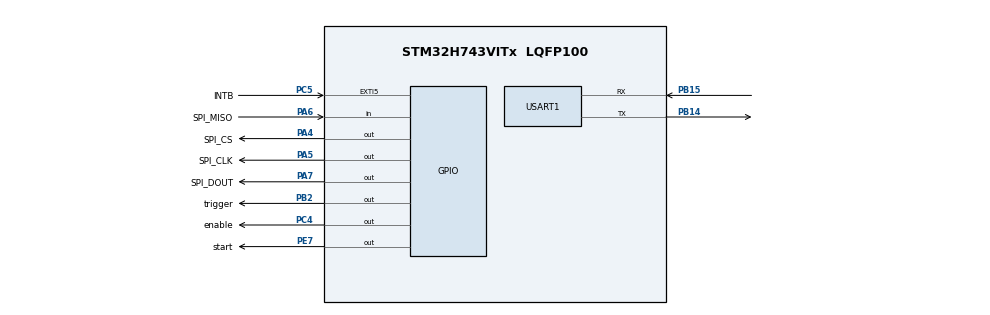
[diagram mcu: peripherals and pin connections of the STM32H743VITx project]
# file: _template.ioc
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CORTEX_M7.AccessPermission-Cortex_Memory_Protection_Unit_Region0_Settings=MPU_REGION_FULL_ACCESS
CORTEX_M7.AccessPermission-Cortex_Memory_Protection_Unit_Region1_Settings=MPU_REGION_FULL_ACCESS
CORTEX_M7.AccessPermission-Cortex_Memory_Protection_Unit_Region2_Settings=MPU_REGION_FULL_ACCESS
CORTEX_M7.AccessPermission-Cortex_Memory_Protection_Unit_Region3_Settings=MPU_REGION_FULL_ACCESS
CORTEX_M7.AccessPermission-Cortex_Memory_Protection_Unit_Region4_Settings=MPU_REGION_FULL_ACCESS
CORTEX_M7.BaseAddress-Cortex_Memory_Protection_Unit_Region0_Settings=0x24000000
CORTEX_M7.BaseAddress-Cortex_Memory_Protection_Unit_Region1_Settings=0x30000000
CORTEX_M7.BaseAddress-Cortex_Memory_Protection_Unit_Region2_Settings=0x30020000
CORTEX_M7.BaseAddress-Cortex_Memory_Protection_Unit_Region3_Settings=0x30040000
CORTEX_M7.BaseAddress-Cortex_Memory_Protection_Unit_Region4_Settings=0x38000000
CORTEX_M7.CPU_DCache=Enabled
CORTEX_M7.CPU_ICache=Enabled
CORTEX_M7.Enable-Cortex_Memory_Protection_Unit_Region0_Settings=MPU_REGION_ENABLE
CORTEX_M7.Enable-Cortex_Memory_Protection_Unit_Region1_Settings=MPU_REGION_ENABLE
CORTEX_M7.Enable-Cortex_Memory_Protection_Unit_Region2_Settings=MPU_REGION_ENABLE
CORTEX_M7.Enable-Cortex_Memory_Protection_Unit_Region3_Settings=MPU_REGION_ENABLE
CORTEX_M7.Enable-Cortex_Memory_Protection_Unit_Region4_Settings=MPU_REGION_ENABLE
CORTEX_M7.IsBufferable-Cortex_Memory_Protection_Unit_Region0_Settings=MPU_ACCESS_BUFFERABLE
CORTEX_M7.IsCacheable-Cortex_Memory_Protection_Unit_Region0_Settings=MPU_ACCESS_CACHEABLE
CORTEX_M7.MPU_Control=MPU_PRIVILEGED_DEFAULT
CORTEX_M7.Size-Cortex_Memory_Protection_Unit_Region0_Settings=MPU_REGION_SIZE_512KB
CORTEX_M7.Size-Cortex_Memory_Protection_Unit_Region1_Settings=MPU_REGION_SIZE_128KB
CORTEX_M7.Size-Cortex_Memory_Protection_Unit_Region2_Settings=MPU_REGION_SIZE_128KB
CORTEX_M7.Size-Cortex_Memory_Protection_Unit_Region3_Settings=MPU_REGION_SIZE_32KB
CORTEX_M7.Size-Cortex_Memory_Protection_Unit_Region4_Settings=MPU_REGION_SIZE_64KB
CORTEX_M7.TypeExtField-Cortex_Memory_Protection_Unit_Region0_Settings=MPU_TEX_LEVEL1
CORTEX_M7.TypeExtField-Cortex_Memory_Protection_Unit_Region1_Settings=MPU_TEX_LEVEL1
CORTEX_M7.TypeExtField-Cortex_Memory_Protection_Unit_Region2_Settings=MPU_TEX_LEVEL1
CORTEX_M7.TypeExtField-Cortex_Memory_Protection_Unit_Region3_Settings=MPU_TEX_LEVEL1
CORTEX_M7.TypeExtField-Cortex_Memory_Protection_Unit_Region4_Settings=MPU_TEX_LEVEL1
Dma.Request0=USART1_RX
Dma.Request1=USART1_TX
Dma.USART1_RX.0.Direction=DMA_PERIPH_TO_MEMORY
Dma.USART1_RX.0.EventEnable=DISABLE
Dma.USART1_RX.0.FIFOMode=DMA_FIFOMODE_DISABLE
Dma.USART1_RX.0.Instance=DMA1_Stream0
Dma.USART1_RX.0.MemDataAlignment=DMA_MDATAALIGN_BYTE
Dma.USART1_RX.0.MemInc=DMA_MINC_ENABLE
Dma.USART1_RX.0.Mode=DMA_NORMAL
Dma.USART1_RX.0.PeriphDataAlignment=DMA_PDATAALIGN_BYTE
Dma.USART1_RX.0.PeriphInc=DMA_PINC_DISABLE
Dma.USART1_RX.0.Polarity=HAL_DMAMUX_REQ_GEN_RISING
Dma.USART1_RX.0.Priority=DMA_PRIORITY_LOW
Dma.USART1_RX.0.RequestNumber=1
Dma.USART1_RX.0.SignalID=NONE
Dma.USART1_RX.0.SyncEnable=DISABLE
Dma.USART1_RX.0.SyncPolarity=HAL_DMAMUX_SYNC_NO_EVENT
Dma.USART1_RX.0.SyncRequestNumber=1
Dma.USART1_RX.0.SyncSignalID=NONE
Dma.USART1_TX.1.Direction=DMA_MEMORY_TO_PERIPH
Dma.USART1_TX.1.EventEnable=DISABLE
Dma.USART1_TX.1.FIFOMode=DMA_FIFOMODE_DISABLE
Dma.USART1_TX.1.Instance=DMA1_Stream1
Dma.USART1_TX.1.MemDataAlignment=DMA_MDATAALIGN_BYTE
Dma.USART1_TX.1.MemInc=DMA_MINC_ENABLE
Dma.USART1_TX.1.Mode=DMA_NORMAL
Dma.USART1_TX.1.PeriphDataAlignment=DMA_PDATAALIGN_BYTE
Dma.USART1_TX.1.PeriphInc=DMA_PINC_DISABLE
Dma.USART1_TX.1.Polarity=HAL_DMAMUX_REQ_GEN_RISING
Dma.USART1_TX.1.Priority=DMA_PRIORITY_LOW
Dma.USART1_TX.1.RequestNumber=1
Dma.USART1_TX.1.SignalID=NONE
Dma.USART1_TX.1.SyncEnable=DISABLE
Dma.USART1_TX.1.SyncPolarity=HAL_DMAMUX_SYNC_NO_EVENT
Dma.USART1_TX.1.SyncRequestNumber=1
Dma.USART1_TX.1.SyncSignalID=NONE
Mcu.Family=STM32H7
Mcu.Name=STM32H743VITx
Mcu.Package=LQFP100
NVIC.DMA1_Stream0_IRQn=true\:0\:0\:false\:false\:true\:false\:true\:true
NVIC.DMA1_Stream1_IRQn=true\:0\:0\:false\:false\:true\:false\:true\:true
NVIC.EXTI9_5_IRQn=true\:0\:0\:false\:false\:true\:true\:true\:true
NVIC.PriorityGroup=NVIC_PRIORITYGROUP_4
NVIC.USART1_IRQn=true\:0\:0\:false\:false\:true\:true\:true\:true
PA13\ (JTMS/SWDIO).Mode=Serial_Wire
PA13\ (JTMS/SWDIO).Signal=DEBUG_JTMS-SWDIO
PA14\ (JTCK/SWCLK).Mode=Serial_Wire
PA14\ (JTCK/SWCLK).Signal=DEBUG_JTCK-SWCLK
PA4.GPIO_Label=SPI_CS
PA4.GPIO_Speed=GPIO_SPEED_FREQ_VERY_HIGH
PA4.PinState=GPIO_PIN_SET
PA4.Signal=GPIO_Output
PA5.GPIO_Label=SPI_CLK
PA5.GPIO_Speed=GPIO_SPEED_FREQ_VERY_HIGH
PA5.PinState=GPIO_PIN_RESET
PA5.Signal=GPIO_Output
PA6.GPIO_Label=SPI_MISO
PA6.GPIO_PuPd=GPIO_PULLUP
PA6.Signal=GPIO_Input
PA7.GPIO_Label=SPI_DOUT
PA7.GPIO_Speed=GPIO_SPEED_FREQ_VERY_HIGH
PA7.PinState=GPIO_PIN_RESET
PA7.Signal=GPIO_Output
PB14.Mode=Asynchronous
PB14.Signal=USART1_TX
PB15.Mode=Asynchronous
PB15.Signal=USART1_RX
PB2.GPIO_Label=trigger
PB2.GPIO_Speed=GPIO_SPEED_FREQ_HIGH
PB2.Signal=GPIO_Output
PC4.GPIO_Label=enable
PC4.GPIO_Speed=GPIO_SPEED_FREQ_HIGH
PC4.Signal=GPIO_Output
PC5.GPIO_Label=INTB
PC5.GPIO_ModeDefaultEXTI=GPIO_MODE_IT_FALLING
PC5.GPIO_PuPd=GPIO_PULLUP
PC5.Signal=GPXTI5
PE7.GPIO_Label=start
PE7.PinState=GPIO_PIN_SET
PE7.Signal=GPIO_Output
PH0-OSC_IN\ (PH0).Mode=HSE-External-Oscillator
PH0-OSC_IN\ (PH0).Signal=RCC_OSC_IN
PH1-OSC_OUT\ (PH1).Mode=HSE-External-Oscillator
PH1-OSC_OUT\ (PH1).Signal=RCC_OSC_OUT
ProjectManager.HeapSize=0x200
ProjectManager.StackSize=0x7400
ProjectManager.TargetToolchain=MDK-ARM V5.32
RCC.ADCFreq_Value=50390625
RCC.APB1Freq_Value=120000000
RCC.APB2Freq_Value=120000000
RCC.APB3Freq_Value=120000000
RCC.APB4Freq_Value=120000000
RCC.CortexFreq_Value=480000000
RCC.D1PPRE=RCC_APB3_DIV2
RCC.D2PPRE1=RCC_APB1_DIV2
RCC.D2PPRE2=RCC_APB2_DIV2
RCC.D3PPRE=RCC_APB4_DIV2
RCC.DIVM1=5
RCC.DIVN1=192
RCC.HCLKFreq_Value=240000000
RCC.HPRE=RCC_HCLK_DIV2
RCC.PLLSourceVirtual=RCC_PLLSOURCE_HSE
RCC.PWR_Regulator_Voltage_Scale=PWR_REGULATOR_VOLTAGE_SCALE0
RCC.ProductRev=revV
RCC.SYSCLKFreq_VALUE=480000000
RCC.SYSCLKSource=RCC_SYSCLKSOURCE_PLLCLK
RCC.USBFreq_Value=480000000
TIM7.Prescaler=239
USART1.VirtualMode-Asynchronous=VM_ASYNC
VP_TIM7_VS_ClockSourceINT.Mode=Enable_Timer
board=custom

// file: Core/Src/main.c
/* USER CODE BEGIN Header */
/**
  ******************************************************************************
  * @file           : main.c
  * @brief          : Main program body
  ******************************************************************************
  * @attention
  *
  * Copyright (c) 2025 STMicroelectronics.
  * All rights reserved.
  *
  * This software is licensed under terms that can be found in the LICENSE file
  * in the root directory of this software component.
  * If no LICENSE file comes with this software, it is provided AS-IS.
  *
  ******************************************************************************
  */
/* USER CODE END Header */
#include "main.h"
#include "dma.h"
#include "tim.h"
#include "usart.h"
#include "gpio.h"

/* USER CODE BEGIN PV */
extern DMA_HandleTypeDef hdma_usart1_rx;
/* USER CODE END PV */

void SystemClock_Config(void);
static void MPU_Initialize(void);
static void MPU_Config(void);

int main(void)
{

  /* Enable I-Cache---------------------------------------------------------*/
  SCB_EnableICache();

  /* Enable D-Cache---------------------------------------------------------*/
  SCB_EnableDCache();

  /* MCU Configuration--------------------------------------------------------*/

  /* Reset of all peripherals, Initializes the Flash interface and the Systick. */
  HAL_Init();

  /* MPU Configuration--------------------------------------------------------*/
  MPU_Config();

  /* Configure the system clock */
  SystemClock_Config();

  /* Initialize all configured peripherals */
  MX_GPIO_Init();
  MX_DMA_Init();
  MX_TIM7_Init();
  MX_USART1_UART_Init();
  /* USER CODE BEGIN 2 */
  TDC_Init();
  TDC7200_preInit_stopmask(125);
  TDC7200_Init();
  TDC_INT_Check();
  /* USER CODE END 2 */

  /* Infinite loop */
  while (1)
  {

  }
}

void SystemClock_Config(void)
{
  RCC_OscInitTypeDef RCC_OscInitStruct = {0};
  RCC_ClkInitTypeDef RCC_ClkInitStruct = {0};

  /** Supply configuration update enable
  */
  HAL_PWREx_ConfigSupply(PWR_LDO_SUPPLY);

  /** Configure the main internal regulator output voltage
  */
  __HAL_PWR_VOLTAGESCALING_CONFIG(PWR_REGULATOR_VOLTAGE_SCALE1);

  while(!__HAL_PWR_GET_FLAG(PWR_FLAG_VOSRDY)) {}

  __HAL_RCC_SYSCFG_CLK_ENABLE();
  __HAL_PWR_VOLTAGESCALING_CONFIG(PWR_REGULATOR_VOLTAGE_SCALE0);

  while(!__HAL_PWR_GET_FLAG(PWR_FLAG_VOSRDY)) {}

  /** Initializes the RCC Oscillators according to the specified parameters
  * in the RCC_OscInitTypeDef structure.
  */
  RCC_OscInitStruct.OscillatorType = RCC_OSCILLATORTYPE_HSE;
  RCC_OscInitStruct.HSEState = RCC_HSE_ON;
  RCC_OscInitStruct.PLL.PLLState = RCC_PLL_ON;
  RCC_OscInitStruct.PLL.PLLSource = RCC_PLLSOURCE_HSE;
  RCC_OscInitStruct.PLL.PLLM = 5;
  RCC_OscInitStruct.PLL.PLLN = 192;
  RCC_OscInitStruct.PLL.PLLP = 2;
  RCC_OscInitStruct.PLL.PLLQ = 2;
  RCC_OscInitStruct.PLL.PLLR = 2;
  RCC_OscInitStruct.PLL.PLLRGE = RCC_PLL1VCIRANGE_2;
  RCC_OscInitStruct.PLL.PLLVCOSEL = RCC_PLL1VCOWIDE;
  RCC_OscInitStruct.PLL.PLLFRACN = 0;
  if (HAL_RCC_OscConfig(&RCC_OscInitStruct) != HAL_OK)
  {
    Error_Handler();
  }

  /** Initializes the CPU, AHB and APB buses clocks
  */
  RCC_ClkInitStruct.ClockType = RCC_CLOCKTYPE_HCLK|RCC_CLOCKTYPE_SYSCLK
                              |RCC_CLOCKTYPE_PCLK1|RCC_CLOCKTYPE_PCLK2
                              |RCC_CLOCKTYPE_D3PCLK1|RCC_CLOCKTYPE_D1PCLK1;
  RCC_ClkInitStruct.SYSCLKSource = RCC_SYSCLKSOURCE_PLLCLK;
  RCC_ClkInitStruct.SYSCLKDivider = RCC_SYSCLK_DIV1;
  RCC_ClkInitStruct.AHBCLKDivider = RCC_HCLK_DIV2;
  RCC_ClkInitStruct.APB3CLKDivider = RCC_APB3_DIV2;
  RCC_ClkInitStruct.APB1CLKDivider = RCC_APB1_DIV2;
  RCC_ClkInitStruct.APB2CLKDivider = RCC_APB2_DIV2;
  RCC_ClkInitStruct.APB4CLKDivider = RCC_APB4_DIV2;

  if (HAL_RCC_ClockConfig(&RCC_ClkInitStruct, FLASH_LATENCY_4) != HAL_OK)
  {
    Error_Handler();
  }
}

/* MPU Configuration */

void MPU_Config(void)
{
  MPU_Region_InitTypeDef MPU_InitStruct = {0};

  /* Disables the MPU */
  HAL_MPU_Disable();

  /** Initializes and configures the Region and the memory to be protected
  */
  MPU_InitStruct.Enable = MPU_REGION_ENABLE;
  MPU_InitStruct.Number = MPU_REGION_NUMBER0;
  MPU_InitStruct.BaseAddress = 0x24000000;
  MPU_InitStruct.Size = MPU_REGION_SIZE_512KB;
  MPU_InitStruct.SubRegionDisable = 0x0;
  MPU_InitStruct.TypeExtField = MPU_TEX_LEVEL1;
  MPU_InitStruct.AccessPermission = MPU_REGION_FULL_ACCESS;
  MPU_InitStruct.DisableExec = MPU_INSTRUCTION_ACCESS_ENABLE;
  MPU_InitStruct.IsShareable = MPU_ACCESS_NOT_SHAREABLE;
  MPU_InitStruct.IsCacheable = MPU_ACCESS_CACHEABLE;
  MPU_InitStruct.IsBufferable = MPU_ACCESS_BUFFERABLE;

  HAL_MPU_ConfigRegion(&MPU_InitStruct);

  /** Initializes and configures the Region and the memory to be protected
  */
  MPU_InitStruct.Number = MPU_REGION_NUMBER1;
  MPU_InitStruct.BaseAddress = 0x30000000;
  MPU_InitStruct.Size = MPU_REGION_SIZE_128KB;
  MPU_InitStruct.IsCacheable = MPU_ACCESS_NOT_CACHEABLE;
  MPU_InitStruct.IsBufferable = MPU_ACCESS_NOT_BUFFERABLE;

  HAL_MPU_ConfigRegion(&MPU_InitStruct);

  /** Initializes and configures the Region and the memory to be protected
  */
  MPU_InitStruct.Number = MPU_REGION_NUMBER2;
  MPU_InitStruct.BaseAddress = 0x30020000;

  HAL_MPU_ConfigRegion(&MPU_InitStruct);

  /** Initializes and configures the Region and the memory to be protected
  */
  MPU_InitStruct.Number = MPU_REGION_NUMBER3;
  MPU_InitStruct.BaseAddress = 0x30040000;
  MPU_InitStruct.Size = MPU_REGION_SIZE_32KB;

  HAL_MPU_ConfigRegion(&MPU_InitStruct);

  /** Initializes and configures the Region and the memory to be protected
  */
  MPU_InitStruct.Number = MPU_REGION_NUMBER4;
  MPU_InitStruct.BaseAddress = 0x38000000;
  MPU_InitStruct.Size = MPU_REGION_SIZE_64KB;

  HAL_MPU_ConfigRegion(&MPU_InitStruct);
  /* Enables the MPU */
  HAL_MPU_Enable(MPU_PRIVILEGED_DEFAULT);

}

void Error_Handler(void)
{
  __disable_irq();
  while (1)
  {
  }
}
